# AC30M1X64 register map
Vendor: ABOV Semiconductor Co., Ltd.; File version: 1.0.0
CPU: CM0 r1p0, little endian, no MPU, no FPU, 2 interrupt priority bits
Registers are 32-bit, read-write, reset 0x0 unless marked. A register's access mark holds for its fields unless they carry their own. Offsets are from the block's base; [hi:lo] are bit positions; {n}, {i} and the like mark numbered series.

## SCU — SYSTEM CONTROL UNIT
Base 0x40000000
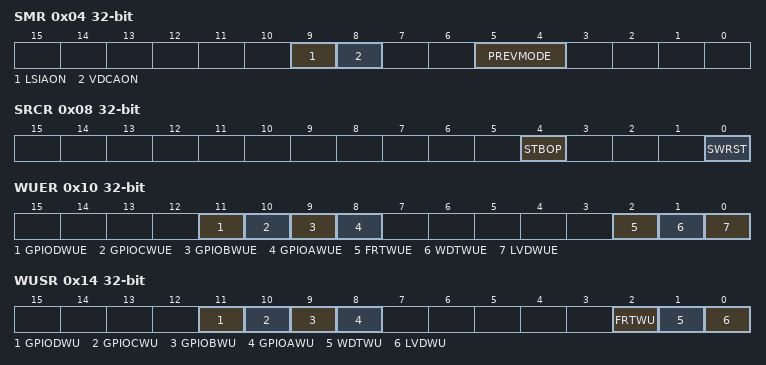
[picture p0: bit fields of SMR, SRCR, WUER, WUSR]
0x04 SMR — System Mode Register
  [9] LSIAON, [8] VDCAON, [5:4] PREVMODE
0x08 SRCR — System Reset Control Register
  [4] STBOP — STBOP pin output polarity select bit
  [0] SWRST — Internal soft reset activation
0x10 WUER — Wakeup Source Enable Register
  [11] GPIODWUE, [10] GPIOCWUE, [9] GPIOBWUE, [8] GPIOAWUE, [2] FRTWUE, [1] WDTWUE, [0] LVDWUE
0x14 WUSR (reset mask 0xF03) — Wakeup Source Status Register
  [11] GPIODWU, [10] GPIOCWU, [9] GPIOBWU, [8] GPIOAWU, [2] FRTWU, [1] WDTWU, [0] LVDWU
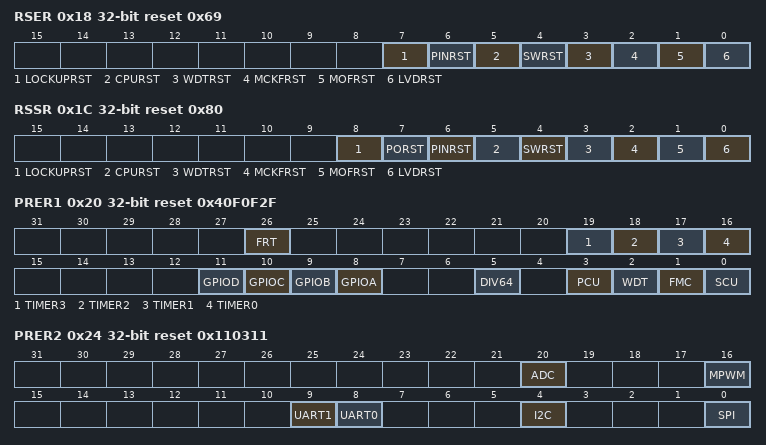
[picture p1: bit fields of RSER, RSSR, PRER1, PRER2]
0x18 RSER reset 0x69 — Reset Source Enable Register
  [7] LOCKUPRST — CPU Lock up reset enable bit
  [6] PINRST — external pin reset enable
  [5] CPURST — CPU request reset enable
  [4] SWRST — software reset enable
  [3] WDTRST — watch dog reset enable
  [2] MCKFRST — MCLK Clock fail reset enable
  [1] MOFRST — MOSC Clock fail reset enable
  [0] LVDRST — LVD reset enable
0x1C RSSR reset 0x80 — Reset Source Status Register
  [8] LOCKUPRST — CPU Lock up reset status
  [7] PORST — power on reset status
  [6] PINRST — extenral pin reset status
  [5] CPURST — cpu request reset status
  [4] SWRST — software reset status
  [3] WDTRST — watchdog timer reset status
  [2] MCKFRST — MCLK failed reset status
  [1] MOFRST — MOSC Clock fail reset status
  [0] LVDRST — lvd reset status
0x20 PRER1 reset 0x40F0F2F — Peripheral Reset Enable Register 1
  [26] FRT — FRT Reset enable
  [19] TIMER3 — TIMER3 Reset enable
  [18] TIMER2 — TIMER2 Reset enable
  [17] TIMER1 — TIMER1 reset enable
  [16] TIMER0 — TIMER0 Reset enable
  [11] GPIOD — GPIOD Reset enable
  [10] GPIOC — GPIOC Reset enable
  [9] GPIOB — GPIOB Reset enable
  [8] GPIOA — GPIOA Reset enable
  [5] DIV64 — DIV64 Reset enable
  [3] PCU — Port Controller unit reset enable
  [2] WDT — WatchDog timer reset enable
  [1] FMC — Flash Memory controller Reset enable
  [0] SCU — Power Management Unit Reset enable
0x24 PRER2 reset 0x110311 — Peripheral Reset Enable Register 2
  [20] ADC — ADC Reset enable
  [16] MPWM — MPWM Reset enable
  [9] UART1 — UART1 Reset enable
  [8] UART0 — UART0 Reset enable
  [4] I2C — I2C Reset enable
  [0] SPI — SPI Reset enable
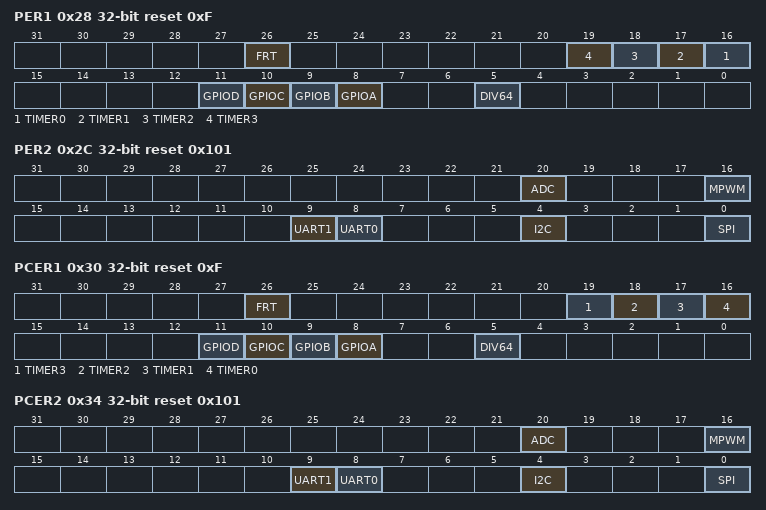
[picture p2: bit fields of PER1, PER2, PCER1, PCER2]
0x28 PER1 reset 0xF — Peripheral Enable Register 1
  [26] FRT, [n+16] TIMER{n} (n=0..3), [11] GPIOD, [10] GPIOC, [9] GPIOB, [8] GPIOA, [5] DIV64
0x2C PER2 reset 0x101 — Peripheral Enable Register 2
  [20] ADC
  [16] MPWM
  [9] UART1
  [8] UART0
  [4] I2C
  [0] SPI — SPI Enable
0x30 PCER1 reset 0xF — Peripheral Clock Enable Register 1
  [26] FRT — FRT clock enable
  [19] TIMER3 — Timer3 clock enable
  [18] TIMER2 — TIMER2 clock enable
  [17] TIMER1 — TIMER1 clock enable
  [16] TIMER0
  [11] GPIOD — GPIOD clock enable
  [10] GPIOC — GPIOC clock enable
  [9] GPIOB — GPIOB clock enable
  [8] GPIOA — GPIOA clock enable
  [5] DIV64
0x34 PCER2 reset 0x101 — Peripheral Clock Enable Register 2
  [20] ADC — ADC clock enable
  [16] MPWM — MPWM clock enable
  [9] UART1 — UART1 clock enable
  [8] UART0
  [4] I2C — I2C clock enable
  [0] SPI — SPI clock enable
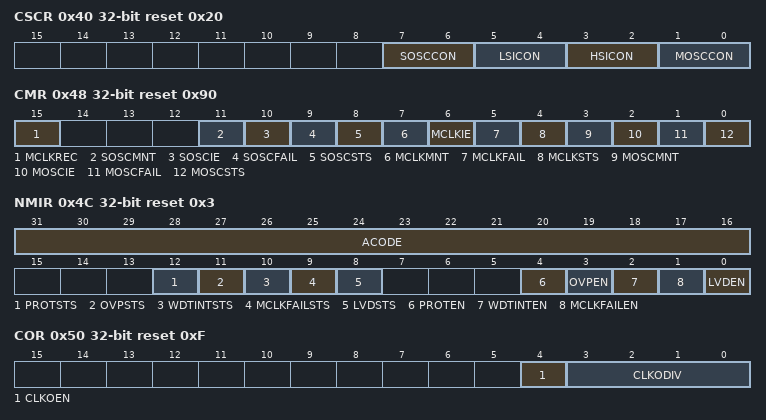
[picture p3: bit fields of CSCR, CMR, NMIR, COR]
0x40 CSCR reset 0x20 — Clock Source Control Register
  [7:6] SOSCCON — External crystal sub oscillator control
  [5:4] LSICON — Low speed internal oscillator control
  [3:2] HSICON — High speed internal oscillator control
  [1:0] MOSCCON — External crystal main oscillator control
0x44 SCCR — System Clock Control Register
  [2:0] MCLKSEL — System clock select
0x48 CMR reset 0x90 — Clock Monitoring Register
  [15] MCLKREC — MCLK failed auto recovery
  [11] SOSCMNT — Sub Oscillator monitoring enable
  [10] SOSCIE — Sub Oscillator fail interrupt enable
  [9] SOSCFAIL — Sub Oscillator fail interrupt flag
  [8] SOSCSTS — Sub Oscillator clock status
  [7] MCLKMNT — MCLK monitor enable
  [6] MCLKIE — MCLK fail Interrupt enable
  [5] MCLKFAIL — MCLK Failed flag
  [4] MCLKSTS — MCLK clock status
  [3] MOSCMNT — External OSC monitor enable
  [2] MOSCIE — external OSC failed interrupt enable
  [1] MOSCFAIL — external OSC failed flag
  [0] MOSCSTS — external OSC status
0x4C NMIR reset 0x3 (reset mask 0xFFFF) — NMI Control Register
  [31:16] ACODE — 0xA32C to write
  [12] PROTSTS
  [11] OVPSTS
  [10] WDTINTSTS
  [9] MCLKFAILSTS
  [8] LVDSTS
  [4] PROTEN
  [3] OVPEN
  [2] WDTINTEN
  [1] MCLKFAILEN
  [0] LVDEN
0x50 COR reset 0xF — Clock Output Register
  [4] CLKOEN — clock output enable
  [3:0] CLKODIV — clock output divider value
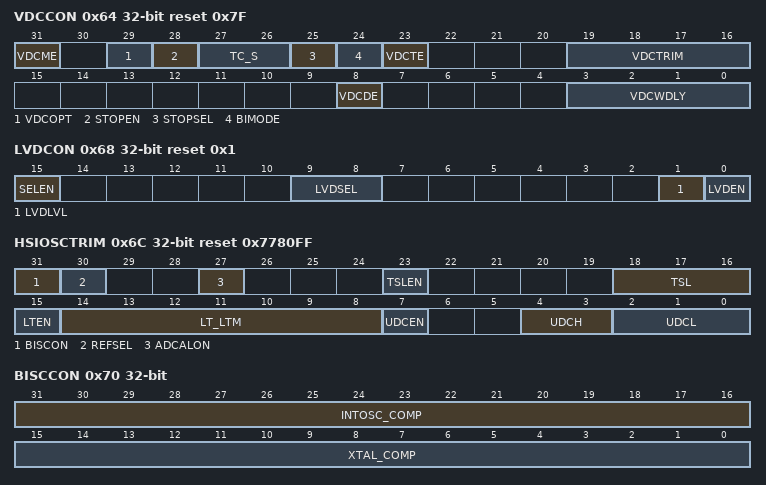
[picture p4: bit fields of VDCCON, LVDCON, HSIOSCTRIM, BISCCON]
0x64 VDCCON reset 0x7F — VDC Control Register
  [31] VDCME wo — VDCMODE value write enable. Write only with VDCMODE value
  [29] VDCOPT wo — VDD18 Up Option Enable bit
  [28] STOPEN wo — VDC STOP MODE Enable bit
  [27:26] TC_S wo — OSC TC Compensation
  [25] STOPSEL wo — VDC STOP MODE Select bit
  [24] BIMODE wo — VDC BIMODE value write enable bit
  [23] VDCTE wo — VDC BGR/BMR trim value write enable
  [19:16] VDCTRIM wo — VDC trim value
  [8] VDCDE wo — VDCWDLY value write enable. Write only with VDCWDLY value
  [3:0] VDCWDLY wo — VDC warm up delay count
0x68 LVDCON reset 0x1 — LVD Control Register
  [15] SELEN wo, [9:8] LVDSEL, [1] LVDLVL ro, [0] LVDEN
0x6C HSIOSCTRIM reset 0x7780FF — High Speed Internal OSC Trim Register
  [31] BISCON — Build in self calibration function enable
  [30] REFSEL — Reference clock select for self-calibration
  [27] ADCALON — Adpaptive calibration clock function enable
  [23] TSLEN wo — TSL trim value write enable
  [18:16] TSL — TSL trim value
  [15] LTEN wo — LTM_LT value write enable
  [14:8] LT_LTM — Internal oscillator LT trim value
  [7] UDCEN wo — UDCH/UDCL value write enable
  [4:3] UDCH — Internal oscillator UDC trim value
  [2:0] UDCL — Internal oscillator UDC trim value
0x70 BISCCON — Build in self calibration control Register
  [31:16] INTOSC_COMP wo, [15:0] XTAL_COMP
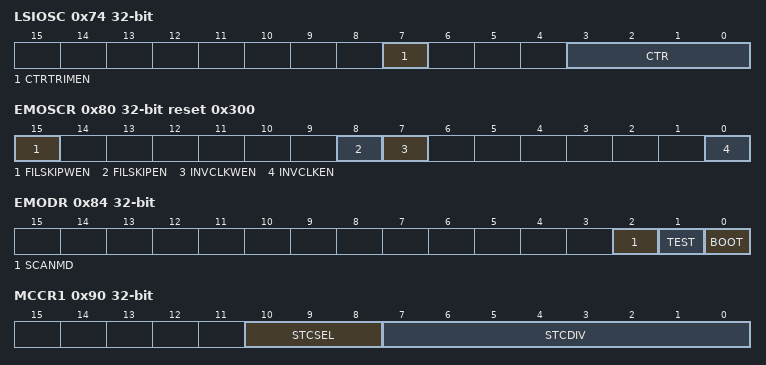
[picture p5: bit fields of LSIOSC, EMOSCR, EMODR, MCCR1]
0x74 LSIOSC — Low Speed Internal OSC Trim Register
  [7] CTRTRIMEN, [3:0] CTR
0x80 EMOSCR reset 0x300 — External Main Oscillator Control Register
  [15] FILSKIPWEN wo — Write enable of bit field FILSKIPEN
  [8] FILSKIPEN — Control External Main Oscillator Filter Skip
  [7] INVCLKWEN wo — Write enable of bit field FILSKIPEN
  [0] INVCLKEN — Control External Main Oscillator CLK invert
0x84 EMODR — External Mode Status Register
  [2] SCANMD — scan mode pin level
  [1] TEST — TEST PIN level
  [0] BOOT — boot pin level
0x90 MCCR1 — Miscellaneous Clock Control Register 1
  [10:8] STCSEL — systick clock source sel
  [7:0] STCDIV — systick divider
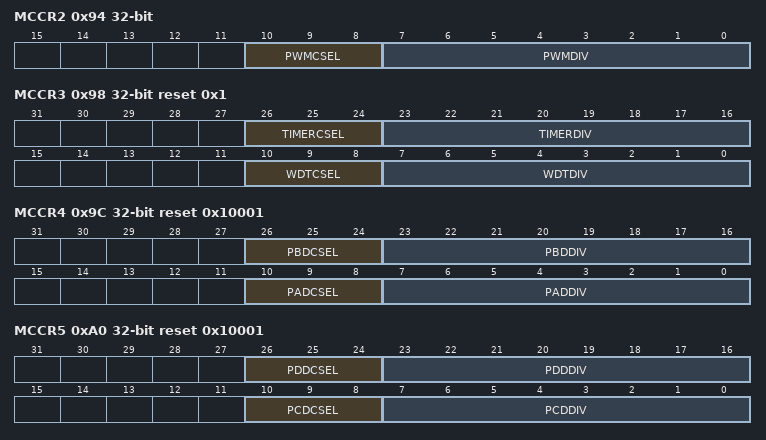
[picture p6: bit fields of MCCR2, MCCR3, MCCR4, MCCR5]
0x94 MCCR2 — Miscellaneous Clock Control Register 2
  [10:8] PWMCSEL — MPWM Clock source sel
  [7:0] PWMDIV — MPWM clock n divider
0x98 MCCR3 reset 0x1 — Miscellaneous Clock Control Register 3
  [26:24] TIMERCSEL — Timer Clock source sel
  [23:16] TIMERDIV — Timer Clock divider
  [10:8] WDTCSEL — WDT clock sel
  [7:0] WDTDIV — WDT divider
0x9C MCCR4 reset 0x10001 — Miscellaneous Clock Control Register 4
  [26:24] PBDCSEL — Debounce Clock for Port B source select
  [23:16] PBDDIV — PORT B Debounce Clock N divider
  [10:8] PADCSEL — Debounce Clock for Port A source select
  [7:0] PADDIV — PORT A Debounce Clock N divider
0xA0 MCCR5 reset 0x10001 — Miscellaneous Clock Control Register 5
  [26:24] PDDCSEL — debouce clock for port D source clock sel
  [23:16] PDDDIV — PORT D debounce divider
  [10:8] PCDCSEL — debouce clock for port C source clock sel
  [7:0] PCDDIV — PORT C debounce divider
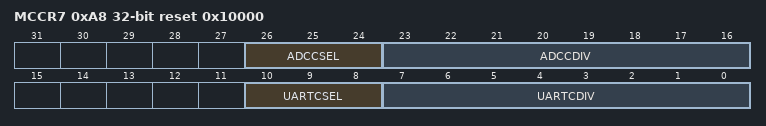
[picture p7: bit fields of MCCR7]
0xA8 MCCR7 reset 0x10000 — Miscellaneous Clock Control Register 7
  [26:24] ADCCSEL — ADC clock source select bit
  [23:16] ADCCDIV — ADC Clock N divider
  [10:8] UARTCSEL — UART clock source select bit
  [7:0] UARTCDIV — UART Clock N divider
